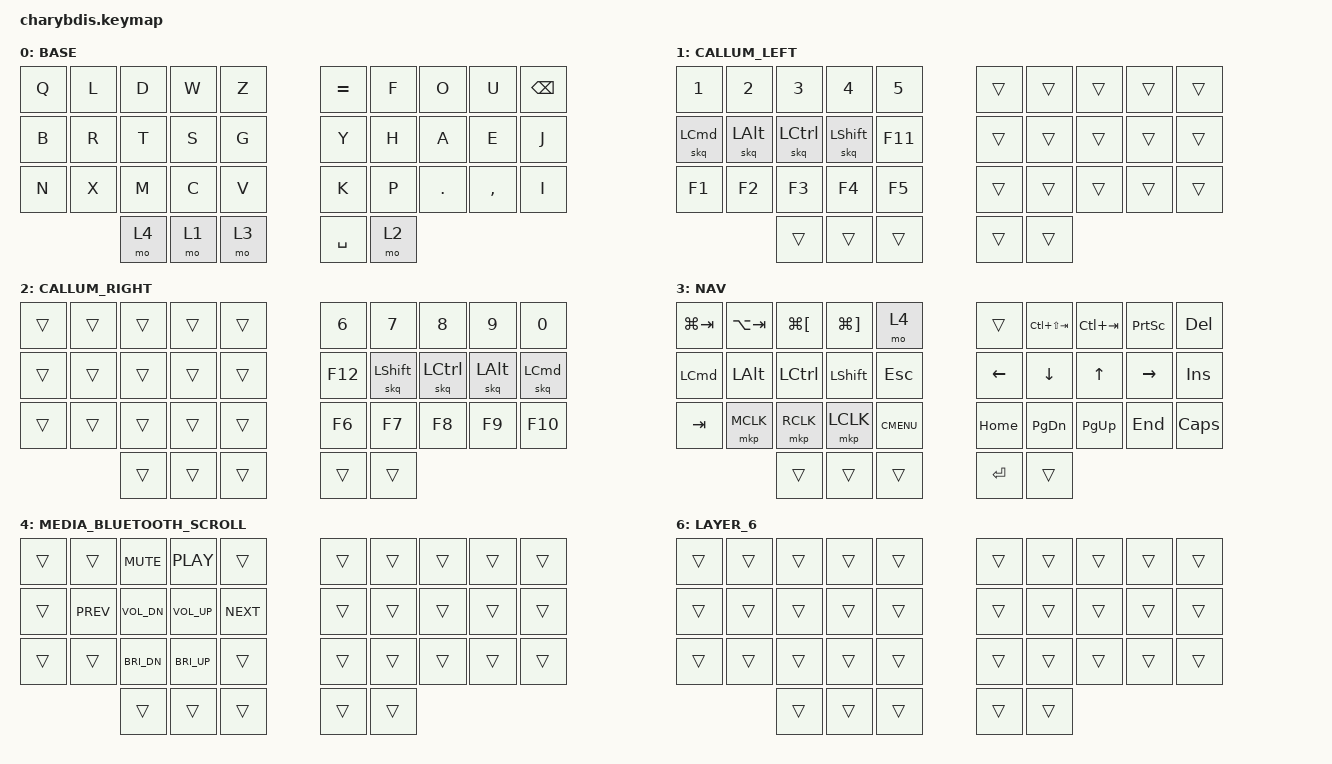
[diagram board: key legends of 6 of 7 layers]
#include <behaviors/mouse_keys.dtsi>
#include <dt-bindings/zmk/mouse.h>
#include <behaviors.dtsi>
#include <dt-bindings/zmk/bt.h>
#include <dt-bindings/zmk/keys.h>
#include <dt-bindings/zmk/pointing.h>

#define U_TAPPING_TERM 200

#if defined(CONFIG_SHIELD_CHARYBDIS_RIGHT)

#define CPI_CYCLE_FORWARD_BINDING &cpi_cycle 1
#define CPI_CYCLE_BACKWARD_BINDING &cpi_cycle 3

#else

#define CPI_CYCLE_FORWARD_BINDING &none
#define CPI_CYCLE_BACKWARD_BINDING &none

#endif

&lt {
    tapping-term-ms = < U_TAPPING_TERM >;
    quick-tap-ms = < U_TAPPING_TERM >;
    flavor = "tap-preferred";
};

/ {
    chosen { zmk,matrix_transform = &default_transform; };
};

/ {
    behaviors {
        skq: sticky_key_quick_release {
            compatible = "zmk,behavior-sticky-key";
            #binding-cells = <1>;
            bindings = <&kp>;
            release-after-ms = <1000>;
            quick-release;
            ignore-modifiers;
            lazy;
        };
    };

    combos {
        compatible = "zmk,combos";

        // ":` ~;'
        combo_double_qoutes {
            bindings = <&kp DOUBLE_QUOTES>;
            key-positions = <1 2>;
        };
        combo_colon {
            bindings = <&kp COLON>;
            key-positions = <2 3>;
        };
        combo_grave {
            bindings = <&kp GRAVE>;
            key-positions = <3 4>;
        };
        combo_tilde {
            bindings = <&kp TILDE>;
            key-positions = <5 6>;
        };
        combo_semi_colon {
            bindings = <&kp SEMICOLON>;
            key-positions = <6 7>;
        };
        combo_single_qoutes {
            bindings = <&kp SINGLE_QUOTE>;
            key-positions = <7 8>;
        };

        // ^#!| &?*$
        combo_caret {
            bindings = <&kp CARET>;
            key-positions = <1 11>;
        };
        combo_hash {
            bindings = <&kp HASH>;
            key-positions = <2 12>;
        };
        combo_exclamation {
            bindings = <&kp EXCLAMATION>;
            key-positions = <3 13>;
        };
        combo_pipe {
            bindings = <&kp PIPE>;
            key-positions = <4 14>;
        };
        combo_ampersand {
            bindings = <&kp AMPERSAND>;
            key-positions = <5 15>;
        };
        combo_question_mark {
            bindings = <&kp QUESTION>;
            key-positions = <6 16>;
        };
        combo_asterisk {
            bindings = <&kp ASTERISK>;
            key-positions = <7 17>;
        };
        combo_dollar {
            bindings = <&kp DOLLAR>;
            key-positions = <8 18>;
        };

        // <> () {} []
        combo_lt {
            bindings = <&kp LESS_THAN>;
            key-positions = <13 14>;
        };
        combo_gt {
            bindings = <&kp GREATER_THAN>;
            key-positions = <15 16>;
        };

        combo_paren_s {
            bindings = <&kp LEFT_PARENTHESIS>;
            key-positions = <12 13>;
        };
        combo_paren_e {
            bindings = <&kp RIGHT_PARENTHESIS>;
            key-positions = <16 17>;
        };

        combo_brace_s {
            bindings = <&kp LEFT_BRACE>;
            key-positions = <11 12>;
        };
        combo_brace_e {
            bindings = <&kp RIGHT_BRACE>;
            key-positions = <17 18>;
        };

        combo_bracket_s {
            bindings = <&kp LEFT_BRACKET>;
            key-positions = <20 11>;
        };
        combo_bracket_e {
            bindings = <&kp RIGHT_BRACKET>;
            key-positions = <18 29>;
        };

        // %F5@\ /-+_
        combo_percent {
            bindings = <&kp PERCENT>;
            key-positions = <11 21>;
        };
        combo_refresh {
            bindings = <&kp F5>;
            key-positions = <12 22>;
        };
        combo_at {
            bindings = <&kp AT>;
            key-positions = <13 23>;
        };
        combo_backslash {
            bindings = <&kp BACKSLASH>;
            key-positions = <14 24>;
        };
        combo_slash {
            bindings = <&kp SLASH>;
            key-positions = <15 25>;
        };
        combo_plus {
            bindings = <&kp PLUS>;
            key-positions = <16 26>;
        };
        combo_minus {
            bindings = <&kp MINUS>;
            key-positions = <17 27>;
        };
        combo_underscore {
            bindings = <&kp UNDERSCORE>;
            key-positions = <18 28>;
        };

        // Keyboard controls / bluetooth layer on master right side 
        combo_bluetooth_layer {
            bindings = <&mo 5>;
            key-positions = <33 34>;
        };
    };

    keymap {
        compatible = "zmk,keymap";

        BASE {
            bindings = <
&kp Q  &kp L  &kp D  &kp W  &kp Z         &kp EQUAL  &kp F  &kp O       &kp U      &kp BACKSPACE
&kp B  &kp R  &kp T  &kp S  &kp G         &kp Y      &kp H  &kp A       &kp E      &kp J
&kp N  &kp X  &kp M  &kp C  &kp V         &kp K      &kp P  &kp PERIOD  &kp COMMA  &kp I
              &mo 4  &mo 1  &mo 3         &kp SPACE  &mo 2
            >;
        };

        CALLUM_LEFT {
                bindings = <
&kp N1     &kp N2     &kp N3      &kp N4       &kp N5           &trans  &trans  &trans  &trans  &trans
&skq LCMD  &skq LALT  &skq LCTRL  &skq LSHIFT  &kp F11          &trans  &trans  &trans  &trans  &trans
&kp F1     &kp F2     &kp F3      &kp F4       &kp F5           &trans  &trans  &trans  &trans  &trans
                      &trans      &trans       &trans           &trans  &trans  
            >;
        };

        CALLUM_RIGHT {
            bindings = <
&trans  &trans  &trans  &trans  &trans         &kp N6   &kp N7       &kp N8      &kp N9     &kp N0         
&trans  &trans  &trans  &trans  &trans         &kp F12  &skq LSHIFT  &skq LCTRL  &skq LALT  &skq LCMD
&trans  &trans  &trans  &trans  &trans         &kp F6   &kp F7       &kp F8      &kp F9     &kp F10
                &trans  &trans  &trans         &trans   &trans
            >;
        };

        NAV {
            bindings = <
&kp LG(TAB)  &kp LA(TAB)  &kp LG(LEFT_BRACKET) &kp LG(RIGHT_BRACKET)  &mo 4                   &trans     &kp LC(LS(TAB))  &kp LC(TAB)  &kp PRINTSCREEN  &kp DELETE
&kp LCMD     &kp LALT     &kp LCTRL            &kp LSHIFT             &kp ESCAPE              &kp LEFT   &kp DOWN         &kp UP       &kp RIGHT        &kp INSERT
&kp TAB      &mkp MCLK    &mkp RCLK            &mkp LCLK              &kp K_CMENU             &kp HOME   &kp PAGE_DOWN    &kp PAGE_UP  &kp END          &kp CAPS
                          &trans               &trans                 &trans                  &kp ENTER  &trans
            >;
        };

        MEDIA_BLUETOOTH_SCROLL {
            bindings = <
&trans  &trans      &kp C_MUTE    &kp C_PLAY    &trans             &trans  &trans  &trans  &trans  &trans
&trans  &kp C_PREV  &kp C_VOL_DN  &kp C_VOL_UP  &kp C_NEXT         &trans  &trans  &trans  &trans  &trans
&trans  &trans      &kp C_BRI_DN  &kp C_BRI_UP  &trans             &trans  &trans  &trans  &trans  &trans
                    &trans        &trans        &trans             &trans  &trans
            >;
        };

        KEYBOARD_CONTROL {
            bindings = <
&trans  &trans  &trans  &trans  &trans          &bt BT_SEL 0  &bt BT_SEL 1    &bt BT_SEL 2  &bt BT_SEL 3  &bt BT_SEL 4  &trans  &trans  &trans
&trans  &trans  &trans  &trans  &trans          &bt BT_CLR    &bt BT_CLR_ALL  &bt BT_NXT    &bt BT_PRV    &trans  &trans  &trans  &trans
&trans  &trans  &trans  &trans  &trans          &kp C_MUTE    &trans          &trans        &trans        &trans  &trans  &trans  &trans
                &trans  &trans  &trans          &trans        &trans
            >;
        };

        LAYER_6 {
            bindings = <
&trans  &trans  &trans  &trans  &trans          &trans  &trans  &trans  &trans  &trans
&trans  &trans  &trans  &trans  &trans          &trans  &trans  &trans  &trans  &trans
&trans  &trans  &trans  &trans  &trans          &trans  &trans  &trans  &trans  &trans
                &trans  &trans  &trans          &trans  &trans
            >;
        };
    };
};
